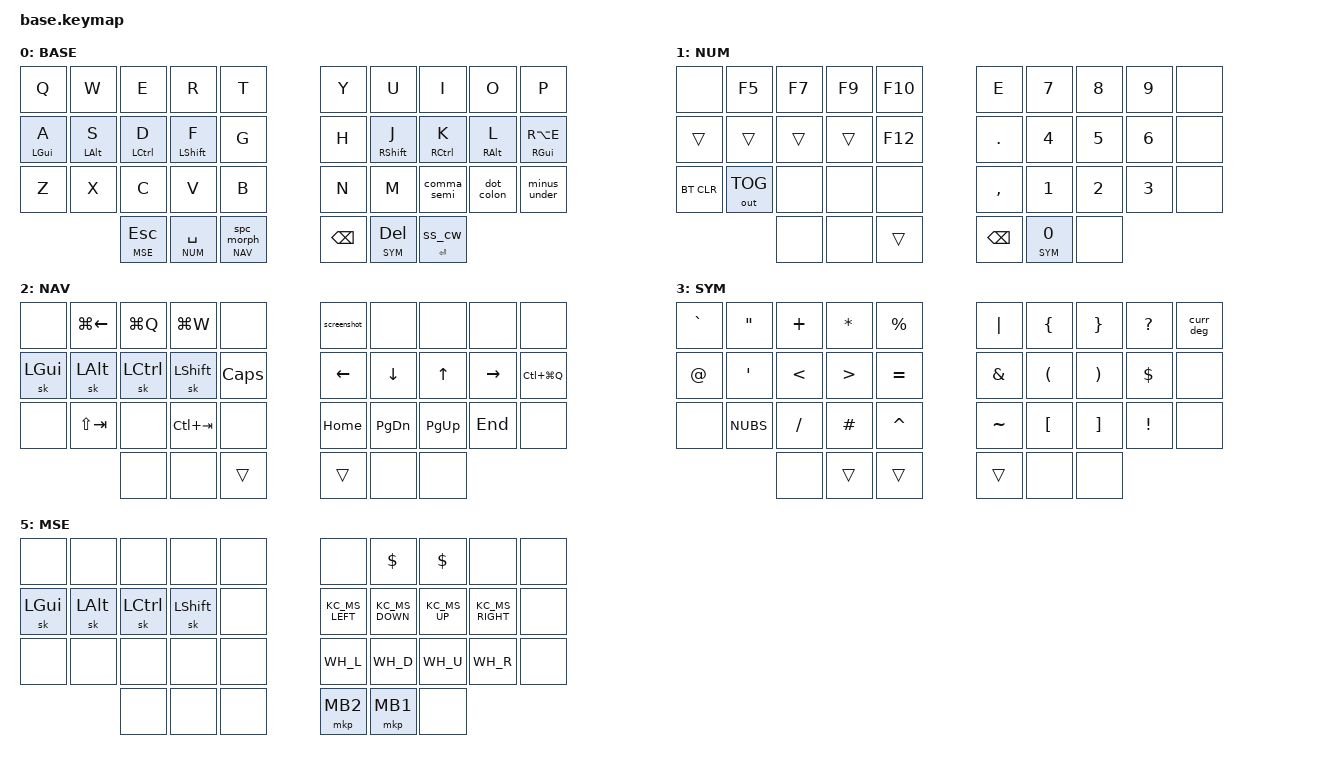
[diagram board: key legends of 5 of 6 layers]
#include <behaviors.dtsi>
#include <dt-bindings/zmk/keys.h>
#include <dt-bindings/zmk/outputs.h>


// layers ID definition
#define BASE 0
#define NUM 1
#define NAV 2
#define SYM 3
#define ADJ 4
#define MSE 5

#define xxx &none
#define ___ &trans

#include "common/combos.dtsi"
#include "common/extra_keys.h"

#include "common/mouse.dtsi"
#if WIRELESS
    #include <dt-bindings/zmk/bt.h>
    #define BTL1  &bt BT_CLR   &bt BT_SEL 2  &pc_connect   &osx_connect
    #define BTL2  xxx          &bt BT_SEL 4  &bt BT_SEL 3  &out OUT_TOG
#else
    #define BTL1  xxx   xxx   xxx   xxx
    #define BTL2  xxx   xxx   xxx   xxx
#endif
#include "common/macros.dtsi"

#ifdef MOUSE_KEYS
    //#include "common/mouse.dtsi"
#endif

// tapping term definition
#define TAP_TERM_MS 200
#define QUICK_TAP_MS 125

// macros definition
#define meh LG(LC(LALT))
#define hyper LG(LC(LS(LALT)))
#define deg RA(LS(N8))
#define HR_APP LG(LS(SPACE))
#define DSK_PREV_W LG(LC(LEFT))
#define DSK_NEXT_W LG(LC(RIGHT))

// OSX specific macros
#define undo LG(Z)
#define redo LG(LS(Z))
#define DSK_PREV LC(LEFT)
#define DSK_NEXT LC(RIGHT)
#define prev_win LG(TAB)
#define next_win LG(LS(TAB))

// 36 keys physical layout
#define LEFT_KEYS 0 1 2 3 4 10 11 12 13 14 20 21 22 23 24 // left-hand keys
#define RIGHT_KEYS 5 6 7 8 9 15 16 17 18 19 25 26 27 28 29 // right-hand keys
#define THUMBS 30 31 32 33 34 35 // thumb keys

// tune mod tap
&mt {
    flavor = "tap-preferred";
    tapping_term_ms = <200>;
};

// layer tap config
&lt {
    flavor = "balanced";
    tapping-term-ms = <TAP_TERM_MS>;
    quick-tap-ms = <QUICK_TAP_MS>;      // double-tap + hold repeats tap-key
};

// tune sticky key
&sk {
    release-after-ms = <1000>;
    quick-release;
};

// sticky layer config
&sl {
    release-after-ms = <700>;
};

// caps word settings
&caps_word {
    continue-list = <UNDERSCORE MINUS BSPC>;
};


// main tree
/ {
    behaviors {
        // HOME ROW MODS
        hml: left_hand_positional_hold_tap {
            compatible = "zmk,behavior-hold-tap";
            #binding-cells = <2>;
            flavor = "balanced";
            tapping-term-ms = <TAP_TERM_MS>;
            quick-tap-ms = <QUICK_TAP_MS>;       // double-tap + hold repeats tap-key
            require-prior-idle-ms = <150>;       // do not activate HOLD during typing flow
            bindings = <&kp>, <&kp>;
            hold-trigger-key-positions = <RIGHT_KEYS THUMBS>;
            hold-trigger-on-release;
        };

        hmr: right_hand_positional_hold_tap {
            compatible = "zmk,behavior-hold-tap";
            #binding-cells = <2>;
            flavor = "balanced";
            tapping-term-ms = <TAP_TERM_MS>;
            quick-tap-ms = <QUICK_TAP_MS>;       // double-tap + hold repeats tap-key
            require-prior-idle-ms = <150>;       // do not activate HOLD during typing flow
            bindings = <&kp>, <&kp>;
            hold-trigger-key-positions = <LEFT_KEYS THUMBS>;
            hold-trigger-on-release;
        };

        // TAP DANCES
        curr_deg: tap_dance_curr_deg {
            compatible = "zmk,behavior-tap-dance";
            #binding-cells = <0>;
            tapping-term-ms = <TAP_TERM_MS>;
            bindings = <&kp DLLR>, <&kp LA(N5)>, <&kp deg>;
        };
        curr_deg_win: tap_dance_curr_deg_win {
            compatible = "zmk,behavior-tap-dance";
            #binding-cells = <0>;
            tapping-term-ms = <TAP_TERM_MS>;
            bindings = <&kp DLLR>, <&macro_euro_win>, <&macro_deg_win>;
        };
        prev_next_song: prev_next_song {
            compatible = "zmk,behavior-tap-dance";
            #binding-cells = <0>;
            tapping-term-ms = <TAP_TERM_MS>;
            bindings = <&kp C_NEXT>, <&kp C_PREV>;
        };
        screenshot: screenshot {
            // single-tap: area selector, double-tap: open screenshot app, triple-tap: full-screen
            compatible = "zmk,behavior-tap-dance";
            #binding-cells = <0>;
            tapping-term-ms = <TAP_TERM_MS>;
            bindings = <&kp LG(LS(N4))>, <&kp LG(LS(N5))>, <&kp LG(LS(N3))>;
        };

        // tap: sticky-shift | lshft + tap: caps-word | hold: set in keymap (HYPER)
        ss_cw: ss_cw {
            compatible = "zmk,behavior-mod-morph";
            #binding-cells = <0>;
            bindings = <&sk RSHFT>, <&caps_word>;
            mods = <(MOD_LSFT|MOD_RSFT)>;
        };
        lt_shft: lt_shft {
            compatible = "zmk,behavior-hold-tap";
            #binding-cells = <2>;
            tapping-term-ms = <TAP_TERM_MS>;
            quick-tap-ms = <QUICK_TAP_MS>;
            flavor = "balanced";
            bindings = <&kp>, <&ss_cw>;
        };

        // tap: space | shft + tap: dot -> space -> sticky shift | hold: activate layer
        spc_morph: spc_morph {
            compatible = "zmk,behavior-mod-morph";
            #binding-cells = <0>;
            bindings = <&kp SPACE>, <&dot_spc>;
            mods = <(MOD_RSFT)>;
        };
        lt_spc: lt_spc {
            compatible = "zmk,behavior-hold-tap";
            #binding-cells = <2>;
            tapping-term-ms = <TAP_TERM_MS>;
            quick-tap-ms = <QUICK_TAP_MS>;
            flavor = "balanced";
            bindings = <&mo>, <&spc_morph>;
        };

        // Alt+Tab swapper, requires PR #1366
        swapper: swapper{
            compatible = "zmk,behavior-tri-state";
            #binding-cells = <0>;
            bindings = <&kt LGUI>, <&kp TAB>, <&kt LGUI>;
            ignored-key-positions = <21>;
        };

        swapper_win: swapper_win{
            compatible = "zmk,behavior-tri-state";
            #binding-cells = <0>;
            bindings = <&kt LALT>, <&kp TAB>, <&kt LALT>;
            ignored-key-positions = <21>;
        };

        //usefull mod-morphs
        esc_kcancel: esc_kcancel {
            compatible = "zmk,behavior-mod-morph";
            #binding-cells = <0>;
            bindings = <&kp ESCAPE>, <&kp K_CANCEL>;
            mods = <(MOD_LSFT|MOD_RSFT)>;
        };
        dot_colon: dot_colon {
            compatible = "zmk,behavior-mod-morph";
            #binding-cells = <0>;
            bindings = <&kp DOT>, <&kp COLON>;
            mods = <(MOD_LSFT)>;
        };
        minus_under: minus_under {
            compatible = "zmk,behavior-mod-morph";
            #binding-cells = <0>;
            bindings = <&kp MINUS>, <&kp UNDER>;
            mods = <(MOD_LSFT)>;
        };
        left_home: left_home {
            compatible = "zmk,behavior-mod-morph";
            #binding-cells = <0>;
            bindings = <&kp LEFT>, <&left_home_nested>;
            keep-mods = <MOD_LCTL>;
            mods = <(MOD_LCTL|MOD_LALT)>;
        };
        left_home_nested: left_home_nested {
            compatible = "zmk,behavior-mod-morph";
            #binding-cells = <0>;
            bindings = <&kp LC(LEFT)>, <&kp HOME>;
            mods = <(MOD_LCTL)>;
        };
        right_end: right_end {
            compatible = "zmk,behavior-mod-morph";
            #binding-cells = <0>;
            bindings = <&kp RIGHT>, <&right_end_nested>;
            keep-mods = <MOD_LCTL>;
            mods = <(MOD_LCTL|MOD_LALT)>;
        };
        right_end_nested: right_end_nested {
            compatible = "zmk,behavior-mod-morph";
            #binding-cells = <0>;
            bindings = <&kp LC(RIGHT)>, <&kp END>;
            mods = <(MOD_LCTL)>;
        };
        comma_semi: comma_semi {
            compatible = "zmk,behavior-mod-morph";
            #binding-cells = <0>;
            bindings = <&kp COMMA>, <&kp SEMICOLON>;
            mods = <(MOD_LSFT)>;
        };
        quest_excl: quest_excl {
            compatible = "zmk,behavior-mod-morph";
            #binding-cells = <0>;
            bindings = <&kp QUESTION>, <&kp EXCLAMATION>;
            mods = <(MOD_LSFT|MOD_RSFT)>;
        };
        single_to_doublequote: single_to_doublequote {
            compatible = "zmk,behavior-mod-morph";
            #binding-cells = <0>;
            bindings = <&kp SINGLE_QUOTE>, <&kp DOUBLE_QUOTES>;
            mods = <(MOD_LSFT|MOD_RSFT)>;
        };
    };

    conditional_layers {
        compatible = "zmk,conditional-layers";
        tri_layer {
            if-layers = <NAV SYM>;
            then-layer = <ADJ>;
        };
    };

    keymap {
        compatible = "zmk,keymap";

        default_layer {
            display-name = "BASE";
            bindings = <
             //╭──────────────┬──────────────┬──────────────┬──────────────┬──────────────╮   ╭──────────────┬──────────────┬──────────────┬──────────────┬──────────────╮
                 &kp Q          &kp W          &kp E          &kp R          &kp T               &kp Y        &kp U          &kp I          &kp O          &kp P
             //├──────────────┼──────────────┼──────────────┼──────────────┼──────────────┤   ├──────────────┼──────────────┼──────────────┼──────────────┼──────────────┤
                 &hml LGUI A    &hml LALT S    &hml LCTRL  D  &hml LSHIFT F  &kp G               &kp H        &hmr RSHIFT J  &hmr RCTRL K   &hmr RALT L   &hmr RGUI RA(E)
             //├──────────────┼──────────────┼──────────────┼──────────────┼──────────────┤   ├──────────────┼──────────────┼──────────────┼──────────────┼──────────────┤
                 &kp Z          &kp X          &kp C          &kp V          &kp B               &kp N        &kp M          &comma_semi    &dot_colon     &minus_under
             //╰──────────────┴──────────────┼──────────────┼──────────────┼──────────────┤   ├──────────────┼──────────────┼──────────────┼──────────────┴──────────────╯
                                              &lt MSE ESC    &lt NUM SPACE  &lt_spc NAV 0        &kp BSPC     &lt SYM DEL   &lt_shft RET 0 
             //                              ╰──────────────┴──────────────┴──────────────╯   ╰──────────────┴──────────────┴──────────────╯
            >;
        };

         num_layer{
            display-name = "NUM";
            bindings = <
             //╭──────────────┬──────────────┬──────────────┬──────────────┬──────────────╮     ╭──────────────┬──────────────┬──────────────┬──────────────┬──────────────╮
                xxx            &kp F5         &kp F7         &kp F9         &kp F10              &kp E          &kp N7         &kp N8         &kp N9         xxx
             //├──────────────┼──────────────┼──────────────┼──────────────┼──────────────┤     ├──────────────┼──────────────┼──────────────┼──────────────┼──────────────┤
                ___            ___            ___            ___            &kp F12              &kp DOT        &kp N4         &kp N5         &kp N6         xxx
             //├──────────────┼──────────────┼──────────────┼──────────────┼──────────────┤     ├──────────────┼──────────────┼──────────────┼──────────────┼──────────────┤
                &bt BT_CLR      &out OUT_TOG  xxx            xxx            xxx                  &kp COMMA      &kp N1         &kp N2         &kp N3         xxx
             //╰──────────────┴──────────────┼──────────────┼──────────────┼──────────────┤     ├──────────────┼──────────────┼──────────────┼──────────────┴──────────────╯
                                              xxx            xxx            ___                  &kp BSPC       &lt SYM N0     xxx
             //                              ╰──────────────┴──────────────┴──────────────╯     ╰──────────────┴──────────────┴──────────────╯
            >;
        };

        nav_layer{
            display-name = "NAV";
            bindings = <
             //╭──────────────┬──────────────┬──────────────┬──────────────┬──────────────╮     ╭──────────────┬──────────────┬──────────────┬──────────────┬──────────────╮
                xxx            &kp LG(LEFT)   &kp LG(Q)      &kp LG(W)      xxx                  &screenshot     xxx            xxx            xxx            xxx
             //├──────────────┼──────────────┼──────────────┼──────────────┼──────────────┤     ├──────────────┼──────────────┼──────────────┼──────────────┼──────────────┤
                &sk LGUI      &sk LALT       &sk LCTRL       &sk LSHFT       &kp CAPS              &kp LEFT       &kp DOWN       &kp UP         &kp RIGHT      &kp LC(LG(Q))
             //├──────────────┼──────────────┼──────────────┼──────────────┼──────────────┤     ├──────────────┼──────────────┼──────────────┼──────────────┼──────────────┤
                xxx            &kp LS(TAB)    xxx            &kp LC(TAB)    xxx                   &kp HOME       &kp PG_DN      &kp PG_UP      &kp END        xxx
             //╰──────────────┴──────────────┼──────────────┼──────────────┼──────────────┤     ├──────────────┼──────────────┼──────────────┼──────────────┴──────────────╯
                                              xxx            xxx            ___                  ___            xxx            xxx
             //                              ╰──────────────┴──────────────┴──────────────╯     ╰──────────────┴──────────────┴──────────────╯
            >;
        };


        symbols {
            display-name = "SYM";
            bindings = <
             //╭──────────────┬──────────────┬──────────────┬──────────────┬──────────────╮     ╭──────────────┬──────────────┬──────────────┬──────────────┬──────────────╮
                &kp GRAVE       &kp DQT        &kp PLUS       &kp ASTRK      &kp PERCENT          &kp PIPE       &kp LBRC       &kp RBRC       &kp QMARK      &curr_deg
             //├──────────────┼──────────────┼──────────────┼──────────────┼──────────────┤     ├──────────────┼──────────────┼──────────────┼──────────────┼──────────────┤
                 &kp AT         &kp SQT        &kp LT         &kp GT         &kp EQUAL            &kp AMPS       &kp LPAR       &kp RPAR       &kp DLLR        xxx
             //├──────────────┼──────────────┼──────────────┼──────────────┼──────────────┤     ├──────────────┼──────────────┼──────────────┼──────────────┼──────────────┤
                xxx             &kp NUBS       &kp FSLH       &kp HASH       &kp CARET            &kp TILDE      &kp LBKT       &kp RBKT       &kp EXCL        xxx
             //╰──────────────┴──────────────┼──────────────┼──────────────┼──────────────┤     ├──────────────┼──────────────┼──────────────┼──────────────┴──────────────╯
                                              xxx            ___            ___                  ___            xxx            xxx
             //                              ╰──────────────┴──────────────┴──────────────╯     ╰──────────────┴──────────────┴──────────────╯
            >;
        };


        adj_layer {
            display-name = "ADJ";
            bindings = <
             //╭──────────────┬──────────────┬──────────────┬──────────────┬──────────────╮     ╭──────────────┬──────────────┬──────────────┬──────────────┬──────────────╮
                xxx            &soft_off      xxx            &to BASE       &bootloader          &bootloader    &kp C_PP       &kp C_NEXT     &kp C_PREV     xxx
             //├──────────────┼──────────────┼──────────────┼──────────────┼──────────────┤     ├──────────────┼──────────────┼──────────────┼──────────────┼──────────────┤
                BTL1                                                        &sys_reset           &sys_reset     &kp C_VOL_DN   &kp C_VOL_UP   &kp C_MUTE     xxx
             //├──────────────┼──────────────┼──────────────┼──────────────┼──────────────┤     ├──────────────┼──────────────┼──────────────┼──────────────┼──────────────┤
                BTL2                                                        xxx                  xxx            &kp C_BRI_DN   &kp C_BRI_UP   xxx            xxx
             //╰──────────────┴──────────────┼──────────────┼──────────────┼──────────────┤     ├──────────────┼──────────────┼──────────────┼──────────────┴──────────────╯
                                              xxx            xxx            xxx                  xxx            xxx            xxx
             //                              ╰──────────────┴──────────────┴──────────────╯     ╰──────────────┴──────────────┴──────────────╯
            >;
        };

        mouse_layer {
            display-name = "MSE";
            bindings = <
             //╭──────────────┬──────────────┬──────────────┬──────────────┬──────────────╮     ╭──────────────┬──────────────┬──────────────┬──────────────┬──────────────╮
                xxx            xxx            xxx            xxx            xxx                   xxx            &kp DLLR       &kp DLLR       xxx            xxx
             //├──────────────┼──────────────┼──────────────┼──────────────┼──────────────┤     ├──────────────┼──────────────┼──────────────┼──────────────┼──────────────┤
                &sk LGUI      &sk LALT       &sk LCTRL       &sk LSHFT      xxx                  &kp KC_MS_LEFT &kp KC_MS_DOWN &kp KC_MS_UP &kp KC_MS_RIGHT   xxx
             //├──────────────┼──────────────┼──────────────┼──────────────┼──────────────┤     ├──────────────┼──────────────┼──────────────┼──────────────┼──────────────┤
                xxx            xxx            xxx            xxx            xxx                   WH_L           WH_D           WH_U           WH_R           xxx
             //╰──────────────┴──────────────┼──────────────┼──────────────┼──────────────┤     ├──────────────┼──────────────┼──────────────┼──────────────┴──────────────╯
                                              xxx            xxx            xxx                   &mkp MB2       &mkp MB1       xxx
             //                              ╰──────────────┴──────────────┴──────────────╯     ╰──────────────┴──────────────┴──────────────╯
            >;
        };

    };
};
